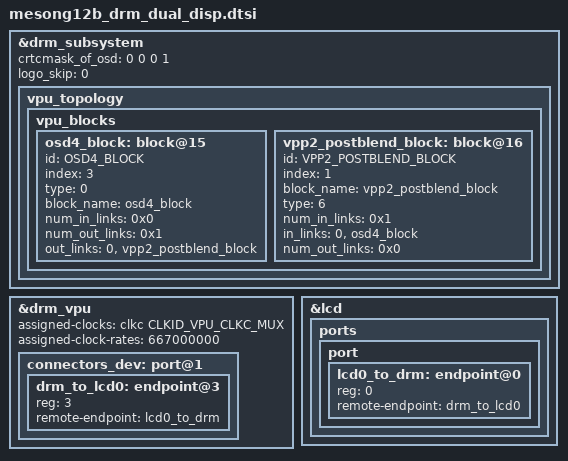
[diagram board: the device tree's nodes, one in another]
// SPDX-License-Identifier: (GPL-2.0+ OR MIT)
/*
 * Copyright (c) 2023 Amlogic, Inc. All rights reserved.
 */

#include "mesong12b_drm.dtsi"

&drm_subsystem {
		crtcmask_of_osd = <0 0 0 1>;
		logo_skip = <0>;
		vpu_topology: vpu_topology {
			vpu_blocks {
				osd4_block: block@15 {
					id = /bits/ 8  <OSD4_BLOCK>;
					index = /bits/ 8  <3>;
					type = /bits/ 8  <0>;
					block_name = "osd4_block";
					num_in_links = /bits/ 8  <0x0>;
					num_out_links = /bits/ 8  <0x1>;
					out_links = <0 &vpp2_postblend_block>;
				};
				vpp2_postblend_block: block@16 {
					id = /bits/ 8  <VPP2_POSTBLEND_BLOCK>;
					index = /bits/ 8  <1>;
					block_name = "vpp2_postblend_block";
					type = /bits/ 8  <6>;
					num_in_links = /bits/ 8  <0x1>;
					in_links = <0 &osd4_block>;
					num_out_links = <0x0>;
				};
			};
		};
};

&drm_vpu {
	assigned-clocks = <&clkc CLKID_VPU_CLKC_MUX>;
	assigned-clock-rates = <667000000>;
	connectors_dev: port@1 {
		drm_to_lcd0: endpoint@3 {
			reg = <3>;
			remote-endpoint = <&lcd0_to_drm>;
		};
	};
};

&lcd {
	ports {
		port {
			#address-cells = <1>;
			#size-cells = <0>;
			lcd0_to_drm: endpoint@0 {
				reg = <0>;
				remote-endpoint = <&drm_to_lcd0>;
			};
		};
	};
};
